# CH32V407 register map
Vendor: WCH Ltd.; File version: 1.0
Registers are 32-bit, read-write, reset 0x0 unless marked. A register's access mark holds for its fields unless they carry their own. Offsets are from the block's base; [hi:lo] are bit positions.

## ETHERNET_DMA — Ethernet: DMA controller operation
Base 0x40407000
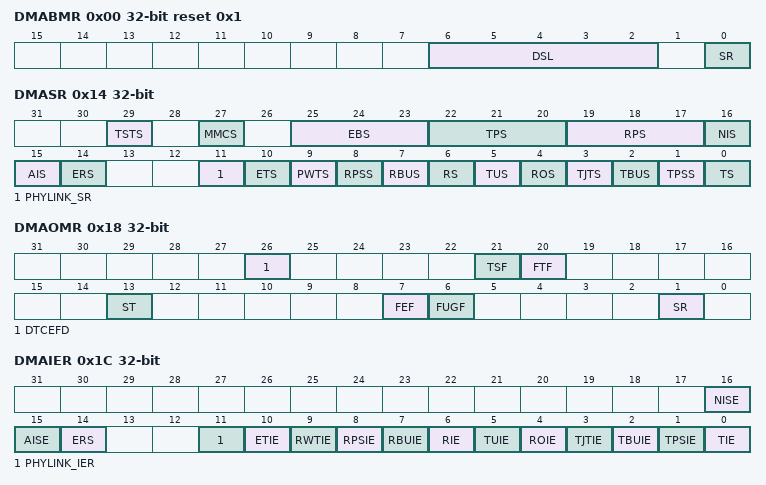
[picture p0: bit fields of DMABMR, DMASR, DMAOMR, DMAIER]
0x00 DMABMR reset 0x1 — Ethernet DMA bus mode register
  [6:2] DSL — Descriptor skip length
  [0] SR — Software reset
0x04 DMATPDR — Ethernet DMA transmit poll demand register
  [31:0] TPDR — Transmit poll demand
0x08 DMARPDR — EHERNET DMA receive poll demand register
  [31:0] RPDR — Receive poll demand
0x0C DMARDLAR — Ethernet DMA receive descriptor list address register
  [31:0] RDLAR — Start of receive list
0x10 DMATDLAR — Ethernet DMA transmit descriptor list address register
  [31:0] TDLAR — Start of transmit list
0x14 DMASR access per field — Ethernet DMA status register
  [29] TSTS ro — Time stamp trigger status
  [27] MMCS ro — MMC status
  [25:23] EBS ro — Error bits status
  [22:20] TPS ro — Transmit process state
  [19:17] RPS ro — Receive process state
  [16] NIS rw — Normal interrupt summary
  [15] AIS rw — Abnormal interrupt summary
  [14] ERS rw — Early receive status
  [11] PHYLINK_SR rw — PHY interrupt state
  [10] ETS rw — Early transmit status
  [9] PWTS rw — Receive watchdog timeout status
  [8] RPSS rw — Receive process stopped status
  [7] RBUS rw — Receive buffer unavailable status
  [6] RS rw — Receive status
  [5] TUS rw — Transmit underflow status
  [4] ROS rw — Receive overflow status
  [3] TJTS rw — Transmit jabber timeout status
  [2] TBUS rw — Transmit buffer unavailable status
  [1] TPSS rw — Transmit process stopped status
  [0] TS rw — Transmit status
0x18 DMAOMR — Ethernet DMA operation mode register
  [26] DTCEFD, [21] TSF, [20] FTF, [13] ST, [7] FEF, [6] FUGF, [1] SR
0x1C DMAIER — Ethernet DMA interrupt enable register
  [16] NISE — Normal interrupt summary enable
  [15] AISE — Abnormal interrupt summary enable
  [14] ERS — Early receive interrupt enable
  [11] PHYLINK_IER — the transceiver connection interrupts the enable bit
  [10] ETIE — Early transmit interrupt enable
  [9] RWTIE — receive watchdog timeout interrupt enable
  [8] RPSIE — Receive process stopped interrupt enable
  [7] RBUIE — Receive buffer unavailable interrupt enable
  [6] RIE — Receive interrupt enable
  [5] TUIE — Underflow interrupt enable
  [4] ROIE — Overflow interrupt enable
  [3] TJTIE — Transmit jabber timeout interrupt enable
  [2] TBUIE — Transmit buffer unavailable interrupt enable
  [1] TPSIE — Transmit process stopped interrupt enable
  [0] TIE — Transmit interrupt enable
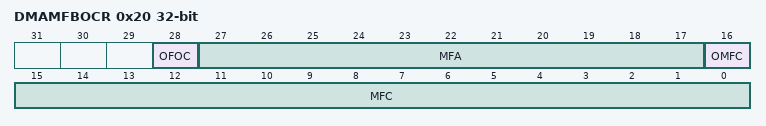
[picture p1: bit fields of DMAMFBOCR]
0x20 DMAMFBOCR ro — Ethernet DMA missed frame and buffer overflow counter register
  [28] OFOC — Overflow bit for FIFO overflow counter
  [27:17] MFA — Missed frames by the application
  [16] OMFC — Overflow bit for missed frame counter
  [15:0] MFC — Missed frames by the controller
0x48 DMACHTDR ro — Ethernet DMA current host transmit descriptor register
  [31:0] HTDAR — Host transmit descriptor address pointer
0x4C DMACHRDR ro — Ethernet DMA current host receive descriptor register
  [31:0] HRDAR — Host receive descriptor address pointer
0x50 DMACHTBAR ro — Ethernet DMA current host transmit buffer address register
  [31:0] HTBAR — Host transmit buffer address pointer
0x54 DMACHRBAR ro — Ethernet DMA current host receive buffer address register
  [31:0] HRBAP — Host receive buffer address pointer

## ARGB
Base 0x40025000
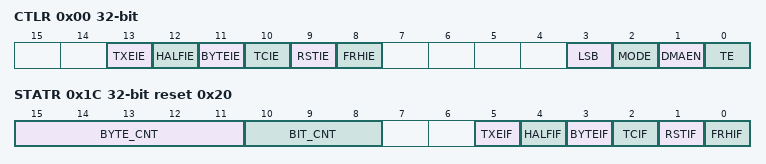
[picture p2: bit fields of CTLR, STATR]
0x00 CTLR — ARGB Control Register
  [13] TXEIE — Send buffer empty interrupt enable
  [12] HALFIE — Data Brush Sends More Than Half Interrupt Enable
  [11] BYTEIE — Byte send completion interrupt enable
  [10] TCIE — Send completion interrupt enable
  [9] RSTIE — RESET code sending is interrupted
  [8] FRHIE — Data refresh cycle end interrupt enabled
  [3] LSB — Data Send Mode Enabling Bits
  [2] MODE — Send mode configuration bits
  [1] DMAEN — DMA Enables
  [0] TE — Send Enable
0x04 DAT_ARR reset 0x3FF — ARGB 0/1 Code Period Configuration Register
  [9:0] DAT_ARR — 0/1 yard cycle
0x08 RST_ARR reset 0x1FFFF — ARGB RESET Code Width Configuration Register
  [16:0] RST_ARR — 0/1 yard cycle
0x0C CCRL — High Level T0H Width Configuration Register
  [9:0] CCRL — 0 yard high level T0H width
0x10 CCRH — 1-yard high-level T1H width configuration register for ARGB
  [9:0] CCRH — 1 yard high level T1H width
0x14 DAT_CYC — ARGB Data Refresh Cycle Length Configuration Register
  [3:0] DAT_CYC — ARGB data refresh cycle length in bytes
0x18 DATAR — ARGB Data Register
  [7:0] DATA — ARGB sends data
0x1C STATR ro reset 0x20 — ARGB State Register
  [15:11] BYTE_CNT — Send byte counters
  [10:8] BIT_CNT — Send bit counter
  [5] TXEIF — Send a buffer empty interrupt flag, writing DATAR will clear the subflag
  [4] HALFIF — Send more than half of the interrupt flag, write 1 to clear
  [3] BYTEIF — The byte sending completion interrupt mark, write 1 to clear
  [2] TCIF — Send the interrupt sign completed, write 1 to clear
  [1] RSTIF — RESET code sends the interrupt mark, writes 1 to clear
  [0] FRHIF — The data refresh cycle has been sent to the interrupt signal, and 1 is written to clear it
0x20 CNTR ro — ARGB Counter Register
  [15:0] CNT — ARGB base counter

## PSRAM
Base 0x40024400
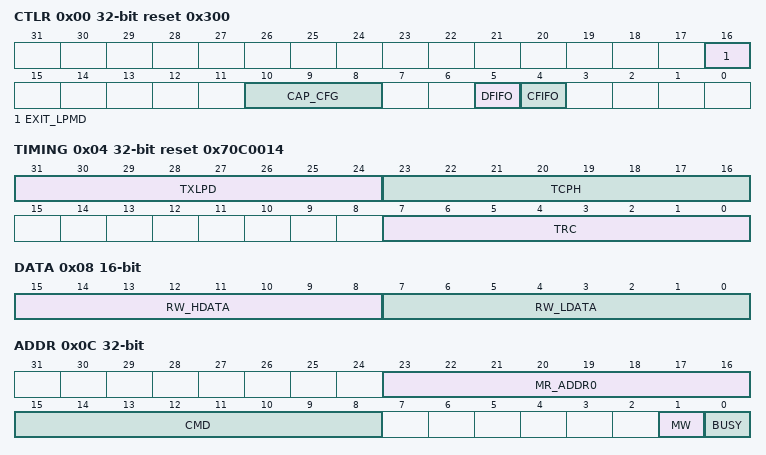
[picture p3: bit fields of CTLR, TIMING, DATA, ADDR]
0x00 CTLR reset 0x300 — PSRAM control register
  [16] EXIT_LPMD — PSRAM exits the current low-power state enable
  [10:8] CAP_CFG — PSRAM capacity configuration
  [5] DFIFO — DMA write operation for clearing FIFO mode Selection
  [4] CFIFO — Empty Read FIFO Method Select
0x04 TIMING reset 0x70C0014 — PSRAM time series register
  [31:24] TXLPD — Sustained pulse width when exiting low power CE_n
  [23:16] TCPH — The minimum interval between two consecutive bursts
  [7:0] TRC — Minimum time for read/write cycles
0x08 DATA 16-bit — PSRAM DATA Register
  [15:8] RW_HDATA — High-byte data written or read
  [7:0] RW_LDATA — Low-byte data written or read
0x0C ADDR — PSRAM Address Register
  [23:16] MR_ADDR0 — The register 0 address to be manipulated
  [15:8] CMD — Commands executed
  [1] MW — Inform PSRAM the nest operation
  [0] BUSY
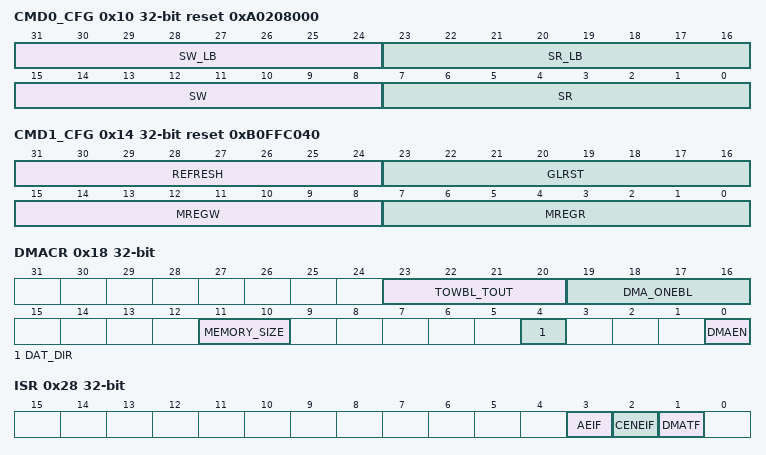
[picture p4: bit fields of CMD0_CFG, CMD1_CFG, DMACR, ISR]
0x10 CMD0_CFG reset 0xA0208000 — PSRAM Command Word 0 Configuration Register
  [31:24] SW_LB — Configurable synchronous write (linear burst) commands
  [23:16] SR_LB — Configurable synchronous read (linear burst) commands
  [15:8] SW — Configurable synchronous write commands
  [7:0] SR — Configurable synchronous read commands
0x14 CMD1_CFG reset 0xB0FFC040 — PSRAM Command Word 1 Configuration Register
  [31:24] REFRESH — Configurable refresh command command
  [23:16] GLRST — Configurable global reset commands
  [15:8] MREGW — Configurable register write commands
  [7:0] MREGR — Configurable register read commands
0x18 DMACR — PSRAM DMA Control Register
  [23:20] TOWBL_TOUT — Pause time between bursts, in HCLK
  [19:16] DMA_ONEBL — DMA burst length
  [11:10] MEMORY_SIZE — Memory Data Width
  [4] DAT_DIR — Data transmission direction
  [0] DMAEN — DMA Enables
0x1C DATA_NUM — PSRAM Data Transmission Quantity Register
  [15:0] DATA_NUM — Number of data transfers
0x20 DMA_MEM_ADDR — Start address register of memory during DMA transmission
  [31:0] DMA_MEM_ADDR — The start address of the memory (single-byte alignment) when DMA is in transit
0x24 DMA_PSRAM_ADDR — Start Address Register of PSRAM during DMA Transmission
  [31:0] DMA_PSRAM_ADDR — The start address of the PSRAM when DMA is transmitted (32 bytes aligned in 4 mode and 16 bytes aligned in 2 mode)
0x28 ISR access per field — PSRAM Interrupt State Register
  [3] AEIF ro — Address error interrupt flag, address exceeds MEM capacity
  [2] CENEIF rw — CEM Error Interrupt Flag, write 1 to clear zero
  [1] DMATF ro — DMA bus transmission completion flag, write 1 to clear zero
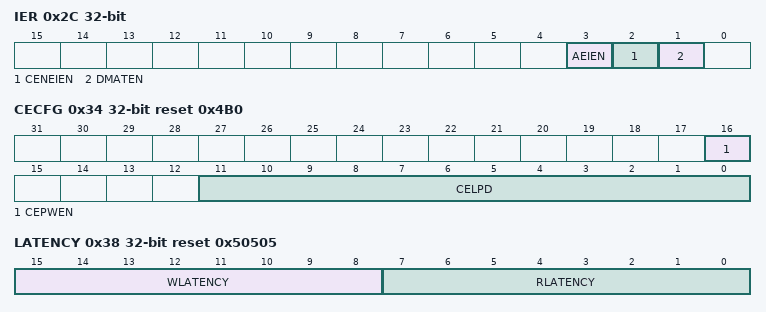
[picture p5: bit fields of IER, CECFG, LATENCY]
0x2C IER — PSRAM Interrupt Error Enable Register
  [3] AEIEN — Address error interrupt enable
  [2] CENEIEN — CEM error interrupt marker enable
  [1] DMATEN — DMA bus transmission completion enable
0x30 STATUS ro — PSRAM controller state machine register
  [4:0] PSRAM_STATE — PSRAM controller state machine
0x34 CECFG reset 0x4B0 — PSRAM CE Pulse Configuration Register
  [16] CEPWEN — CE pulse width detection enables
  [11:0] CELPD — Maximum duration of CE low pulse (excluding withdrawal of half sleep): T= N*PSRAM clock period
0x38 LATENCY reset 0x50505 — PSRAM Read/Write Delay Register
  [15:8] WLATENCY — Write the delay
  [7:0] RLATENCY — Read the delay
